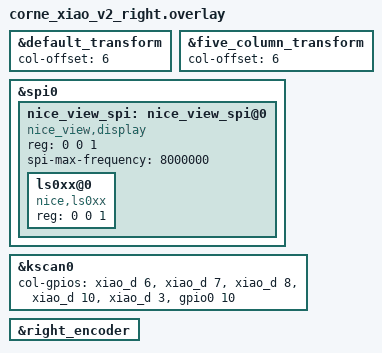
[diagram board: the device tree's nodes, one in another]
#include "corne_xiao_v2.dtsi"

&default_transform {
    col-offset = <6>;
};

&five_column_transform {
    col-offset = <6>;
};

&spi0 {
    status = "okay";

    nice_view_spi: nice_view_spi@0 {
        compatible = "nice_view,display";
        reg = <0 0 1>;
        spi-max-frequency = <8000000>;

        ls0xx@0 {
            compatible = "nice,ls0xx";
            reg = <0 0 1>;
        };
    };
};


&kscan0 {
    col-gpios
        = <&xiao_d 6 GPIO_ACTIVE_HIGH>
        , <&xiao_d 7 GPIO_ACTIVE_HIGH> 
        , <&xiao_d 8 GPIO_ACTIVE_HIGH>
        , <&xiao_d 10 GPIO_ACTIVE_HIGH>
        , <&xiao_d 3 GPIO_ACTIVE_HIGH>
        , <&gpio0 10 GPIO_ACTIVE_HIGH>
        ;
};

&right_encoder {
    status = "okay";
};
